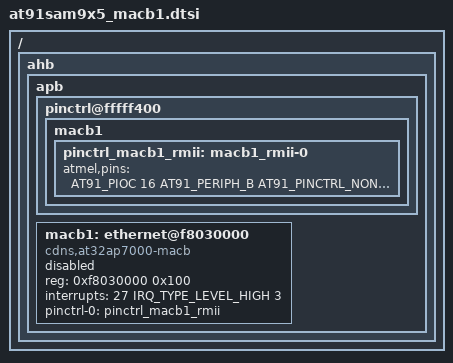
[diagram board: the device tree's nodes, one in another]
/*
 * at91sam9x5_macb1.dtsi - Device Tree Include file for AT91SAM9x5 SoC with 2
 * Ethernet interfaces.
 *
 * Copyright (C) 2013 Boris BREZILLON <b.brezillon@overkiz.com>
 *
 * Licensed under GPLv2.
 */

#include <dt-bindings/pinctrl/at91.h>
#include <dt-bindings/interrupt-controller/irq.h>

/ {
	ahb {
		apb {
			pinctrl@fffff400 {
				macb1 {
					pinctrl_macb1_rmii: macb1_rmii-0 {
						atmel,pins =
							<AT91_PIOC 16 AT91_PERIPH_B AT91_PINCTRL_NONE	/* PC16 periph B */
							 AT91_PIOC 18 AT91_PERIPH_B AT91_PINCTRL_NONE	/* PC18 periph B */
							 AT91_PIOC 19 AT91_PERIPH_B AT91_PINCTRL_NONE	/* PC19 periph B */
							 AT91_PIOC 20 AT91_PERIPH_B AT91_PINCTRL_NONE	/* PC20 periph B */
							 AT91_PIOC 21 AT91_PERIPH_B AT91_PINCTRL_NONE	/* PC21 periph B */
							 AT91_PIOC 27 AT91_PERIPH_B AT91_PINCTRL_NONE	/* PC27 periph B */
							 AT91_PIOC 28 AT91_PERIPH_B AT91_PINCTRL_NONE	/* PC28 periph B */
							 AT91_PIOC 29 AT91_PERIPH_B AT91_PINCTRL_NONE	/* PC29 periph B */
							 AT91_PIOC 30 AT91_PERIPH_B AT91_PINCTRL_NONE	/* PC30 periph B */
							 AT91_PIOC 31 AT91_PERIPH_B AT91_PINCTRL_NONE>;	/* PC31 periph B */
					};
				};
			};

			macb1: ethernet@f8030000 {
				compatible = "cdns,at32ap7000-macb", "cdns,macb";
				reg = <0xf8030000 0x100>;
				interrupts = <27 IRQ_TYPE_LEVEL_HIGH 3>;
				pinctrl-names = "default";
				pinctrl-0 = <&pinctrl_macb1_rmii>;
				status = "disabled";
			};
		};
	};
};
